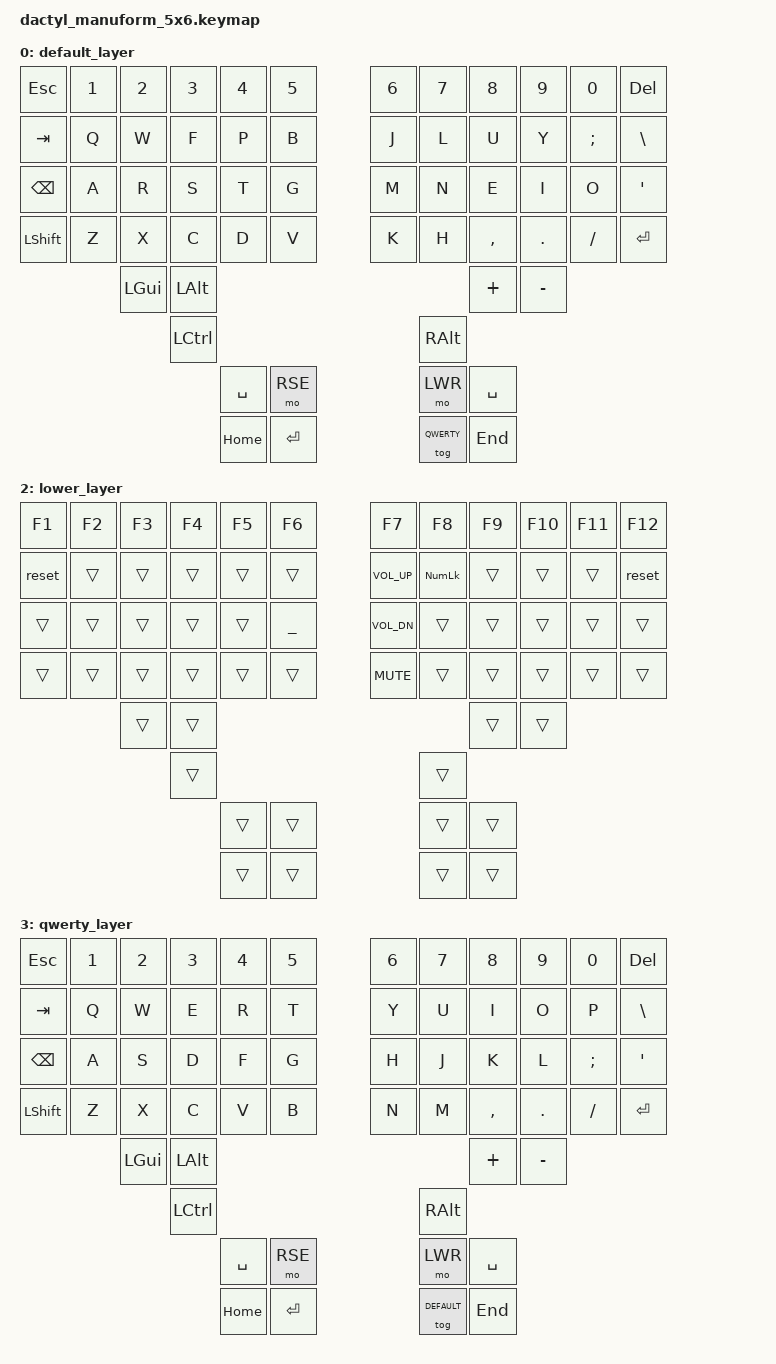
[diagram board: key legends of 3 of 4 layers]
#include <behaviors.dtsi>
#include <dt-bindings/zmk/keys.h>
#include <dt-bindings/zmk/bt.h>
#include <dt-bindings/zmk/outputs.h>

#define DEFAULT 0
#define RSE 1
#define LWR 2
#define QWERTY 3

/ {
    keymap {
        compatible = "zmk,keymap";

        default_layer {
            bindings = <
                &kp ESC   &kp N1 &kp N2 &kp N3 &kp N4 &kp N5              &kp N6 &kp N7 &kp N8    &kp N9  &kp N0   &kp DEL
                &kp TAB   &kp Q  &kp W  &kp F  &kp P  &kp B               &kp J  &kp L  &kp U     &kp Y   &kp SEMI    &kp BSLH
                &kp BSPC  &kp A  &kp R  &kp S  &kp T  &kp G               &kp M  &kp N  &kp E     &kp I   &kp O  &kp SQT
                &kp LSHFT &kp Z  &kp X  &kp C  &kp D  &kp V               &kp K  &kp H  &kp COMMA &kp DOT &kp FSLH &kp RET
                                 &kp LGUI &kp LALT                                      &kp PLUS &kp MINUS
                                           &kp LCTRL                               &kp RALT
                                            &kp SPACE   &mo RSE             &mo LWR  &kp SPACE
                                            &kp HOME &kp RET                &tog QWERTY &kp END
            >;
        };

        raise {
            bindings = <
                &kp GRAVE &kp EXCL &kp AT &kp HASH &kp DOLLAR &kp PRCNT                &kp CARET &kp AMPS   &kp STAR   &kp LPAR &kp RPAR &kp PG_UP
                &trans  &trans &kp UP &trans &trans &kp LBRC                &kp RBRC &kp KP_N7  &kp KP_N8   &kp KP_N9 &kp KP_N0    &kp PG_DN
                &trans  &kp LEFT &kp DOWN &kp RIGHT &trans &kp LPAR                &kp RPAR &kp KP_N4 &kp KP_N5 &kp KP_N6 &kp PLUS &kp EQUAL
                &trans  &trans &trans &trans &trans &kp LBKT                &kp RBKT &kp KP_N1   &kp KP_N2   &kp KP_N3 &kp MINUS    &trans
                               &trans &trans                                              &kp PLUS &kp EQUAL
                                             &trans &trans                &trans &trans
                                             &trans &trans                &trans &trans
                                             &trans &trans                &kp DEL &trans
            >;
        };

        lower_layer {
            bindings = <
                &kp F1  &kp F2 &kp F3 &kp F4 &kp F5 &kp F6                &kp F7 &kp F8 &kp F9 &kp F10 &kp F11 &kp F12
                &reset  &trans &trans &trans &trans &trans                &kp K_VOL_UP &kp KP_NUM &trans &trans &trans &reset
                &trans  &trans &trans &trans &trans &kp UNDER                &kp K_VOL_DN &trans &trans &trans &trans &trans
                &trans  &trans &trans &trans &trans &trans                 &kp K_MUTE &trans &trans &trans &trans &trans
                               &trans &trans                                            &trans &trans
                                             &trans                              &trans
                                             &trans  &trans               &trans &trans
                                             &trans  &trans               &trans &trans
            >;
        };

        qwerty_layer {
            bindings = <
                &kp ESC   &kp N1 &kp N2 &kp N3 &kp N4 &kp N5              &kp N6 &kp N7 &kp N8    &kp N9  &kp N0   &kp DEL
                &kp TAB   &kp Q  &kp W  &kp E  &kp R  &kp T               &kp Y  &kp U  &kp I     &kp O   &kp P     &kp BSLH
                &kp BSPC  &kp A  &kp S  &kp D  &kp F  &kp G               &kp H  &kp J  &kp K     &kp L   &kp SEMI &kp SQT
                &kp LSHFT &kp Z  &kp X  &kp C  &kp V  &kp B               &kp N &kp M  &kp COMMA &kp DOT &kp FSLH &kp RET
                                 &kp LGUI &kp LALT                                      &kp PLUS &kp MINUS
                                           &kp LCTRL                               &kp RALT
                                            &kp SPACE   &mo RSE             &mo LWR  &kp SPACE
                                            &kp HOME &kp RET                &tog DEFAULT &kp END
            >;
        };
    };
};
